# EMIF1 register map
Vendor: Texas Instruments
Peripheral module from a debugger description file (folder omap4460).
Registers are 32-bit, access per field, reset 0x0 unless marked. A register's access mark holds for its fields unless they carry their own. Offsets are as the file gives them; lines under a group give offsets from that group; [hi:lo] are bit positions; {n}, {i} and the like mark numbered series; 'fields as' and 'values as' point back to an identical list; <NAME> marks a mode.

## EMIF1
0x00 EMIF_MOD_ID_REV ro reset not defined — Revision number register
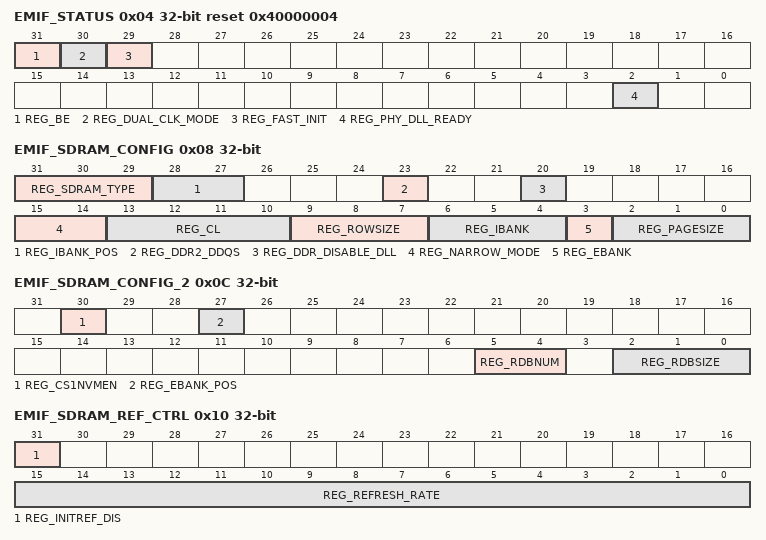
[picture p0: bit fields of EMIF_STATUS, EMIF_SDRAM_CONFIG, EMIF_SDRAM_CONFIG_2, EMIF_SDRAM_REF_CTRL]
0x04 EMIF_STATUS ro reset 0x40000004 — SDRAM Status Register (STATUS)
  [31] REG_BE — Big endian mode select for 8 and 16-bit devices, set to 1 for big endian or 0 for little endian operation.
  [30] REG_DUAL_CLK_MODE — Dual Clock mode. Defines whether the L3_clk and EMIF_FCLK clock are asynchronous. L3_clk and EMIF_FCLK clock are asynchronous, if set to 1.
  [29] REG_FAST_INIT — Fast Init. Defines whether the EMIF fast initialization mode has been enabled. Fast initialization is enabled if set to 1.
  [2] REG_PHY_DLL_READY — DDR PHY Ready. Reflects the value on the phy_ready port (active high) that defines whether the DDR PHY is ready for normal operation. The DDR PHY is ready for normal operation, if set to 1.
0x08 EMIF_SDRAM_CONFIG rw (reset mask 0x70F0000) — SDRAM Config Register. A write to this register will cause the EMIF to start the SDRAM initialization sequence if it was not performed previously because [31] REG_INITREF_DIS was a zero.
  [31:29] REG_SDRAM_TYPE — SDRAM Type selection. Set to 4 for LPDDR2-S4, Set to 5 for LPDDR2-S2 All other value are reserved.
  [28:27] REG_IBANK_POS — Internal bank position. Set to 0 to assign internal bank address bits from L3 address as shown in and . Set to 1, 2, or 3 to assign internal bank address bits from L3 address as shown in , , and .
  [23] REG_DDR2_DDQS — DDR2 differential DQS enable. Set to 0 for single-ended DQS. Set to 1 for differential DQS. This bit is only for DDR2 mode, because the device supports LPDDR2; this bit is don’t care.
  [20] REG_DDR_DISABLE_DLL — Disable DLL select. Set to 1 to disable DLL inside SDRAM.
  [15:14] REG_NARROW_MODE — SDRAM data bus width. Set to 0 for 32-bit and set to 1 for 16-bit. All other values are reserved.
  [13:10] REG_CL — CAS Latency (referred to as read latency (RL) in some SDRAM specs). The value of this field defines the CAS latency to be used when accessing connected SDRAM devices. Value of 3, 4, 5, 6, 7, and 8 (CAS latency of 3, 4, 5, 6, 7, and 8) are supported for LPDDR2-SDRAM. All other values are reserved. Also program the EMIF_DDR_PHY_CTRL_1[3:0] REG_READ_LATENCY
  [9:7] REG_ROWSIZE — Row Size. Defines the number of row address bits of connected SDRAM devices. Set to 0 for 9 row bits, Set to 1 for 10 row bits, Set to 2 for 11 row bits, Set to 3 for 12 row bits, Set to 4 for 13 row bits, Set to 5 for 14 row bits, Set to 6 for 15 row bits, Set to 7 for 16 row bits. This field is only used when EMIF_SDRAM_CONFIG[28:27] REG_IBANK_POS field is set to 1, 2, or 3 or REG_EBANK_POS field in EMIF_SDRAM_CONFIG_2 register is set to 1.
  [6:4] REG_IBANK — Internal Bank setup. Defines number of banks inside connected SDRAM devices. Set to 0 for 1 bank, Set to 1 for 2 banks, Set to 2 for 4 banks, Set to 3 for 8 banks. All other values are reserved.
  [3] REG_EBANK — External chip select setup. Defines whether SDRAM accesses will use 1 or 2 chip select lines. Set to 0 to use pad_cs_o_n[0] only. Set to 1 to use pad_cs_o_n[1:0]. This bit will automatically be set to 0 if EMIF_SDRAM_CONFIG_2[30] REG_CS1NVMEN field is set to 1.
  [2:0] REG_PAGESIZE — Page Size. Defines the internal page size of connected SDRAM devices. Set to 0 for 256-word page (8 column bits), Set to 1 for 512-word page (9 column bits), Set to 2 for 1024-word page (10 column bits), Set to 3 for 2048-word page (11 column bits). All other values are reserved.
0x0C EMIF_SDRAM_CONFIG_2 (reset mask 0xBFFFFFC8)
  [30] REG_CS1NVMEN rw — CS1 LPDDR2-NVM enable. Set to 1 if LPDDR2-NVM is connected to CS1. This bit will automatically be set to 0 if reg_sdram_type field in the SDRAM Config register is not set to LPDDR2.
  [27] REG_EBANK_POS rw — External bank position. Set to 0 to assign external bank address bits from lower OCP address as shown in tables. Set to 1 to assign external bank address bits from higher OCP address bits as shown in tables.
  [5:4] REG_RDBNUM rw — Row Buffer setup. Defines number of row buffers inside connected LPDDR2-NVM devices. Set to 0 for 1 row buffer, set to 1 for 2 row buffers, set to 2 for 4 row buffers, and set to 3 for 8 row buffers. All other values are reserved.
  [2:0] REG_RDBSIZE rw — Row Data Buffer Size. Defines the row data buffer size of connected LPDDR2-NVM devices. Set to 0 for 32 bytes, set to 1 for 64 bytes, set to 2 for 128 bytes, set to 3 for 256 bytes, set to 4 for 512 bytes, set to 5 for 1024 bytes, set to 6 for 2048 bytes, and set to 7 for 4096 bytes.
0x10 EMIF_SDRAM_REF_CTRL — SDRAM Refresh Control Register
  [31] REG_INITREF_DIS rw — Initialization and Refresh disable. When set to 1, EMIF will disable SDRAM initialization and refreshes, but will carry out SDRAM write/read transactions.
  [15:0] REG_REFRESH_RATE rw — Refresh Rate. Value in this field is used to define the rate at which connected SDRAM devices will be refreshed. SDRAM refresh rate = DDR_PHY_CLK / REG_REFRESH_RATE. To avoid lock-up situations, the programmer must not program REG_REFRESH_RATE &lt; (6 × REG_T_RFC). For DDR_PHY_CLK description, see, .
0x14 EMIF_SDRAM_REF_CTRL_SHDW — SDRAM Refresh Control Shadow Register
  [15:0] REG_REFRESH_RATE_SHDW rw — Shadow field for REG_REFRESH_RATE. This field is loaded intoEMIF_SDRAM_REF_CTRL[15:0] REG_REFRESH_RATE field when SIdleAck is asserted. This register is not auto corrected when the value is invalid.
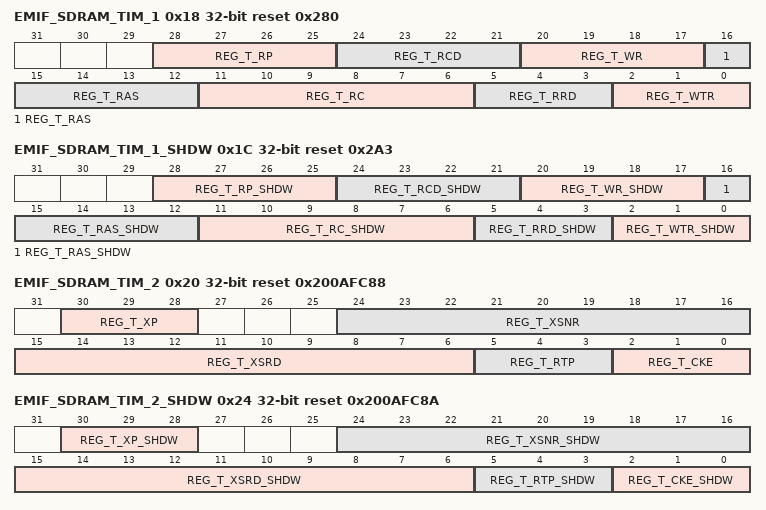
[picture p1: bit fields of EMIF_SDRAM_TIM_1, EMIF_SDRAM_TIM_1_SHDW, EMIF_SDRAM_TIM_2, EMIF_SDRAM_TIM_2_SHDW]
0x18 EMIF_SDRAM_TIM_1 reset 0x280 (reset mask 0xFFFFFFC0) — SDRAM Timing 1 Register. If this register is byte written, care must be taken that all the fields are written before performing any accesses to the SDRAM.
  [28:25] REG_T_RP rw — Minimum number of DDR clock cycles from Precharge to Activate or Refresh, minus one.
  [24:21] REG_T_RCD rw — Minimum number of DDR clock cycles from Activate to Read or Write, minus one.
  [20:17] REG_T_WR rw — Minimum number of DDR clock cycles from last Write transfer to Precharge, minus one.
  [16:12] REG_T_RAS rw — Minimum number of DDR clock cycles from Activate to Precharge, minus one. reg_t_ras value needs to be bigger than or equal to reg_t_rcd value.
  [11:6] REG_T_RC rw — Minimum number of DDR clock cycles from Activate to Activate, minus one.
  [5:3] REG_T_RRD rw — Minimum number of DDR clock cycles from Activate to Activate for a different bank, minus one. For an 8-bank, this field must be equal to ((tFAW/(4*tCK))-1).
  [2:0] REG_T_WTR rw — Minimum number of DDR clock cycles from last Write to Read, minus one.
0x1C EMIF_SDRAM_TIM_1_SHDW reset 0x2A3 — SDRAM Timing 1 Shadow Register
  [28:25] REG_T_RP_SHDW rw — Shadow field for REG_T_RP. This field is loaded intoEMIF_SDRAM_TIM_1[28:25] REG_T_RP field when SIdleAck is asserted.
  [24:21] REG_T_RCD_SHDW rw — Shadow field for REG_T_RCD. This field is loaded intoEMIF_SDRAM_TIM_1[24:21] REG_T_RCD field when SIdleAck is asserted.
  [20:17] REG_T_WR_SHDW rw — Shadow field for REG_T_WR. This field is loaded intoEMIF_SDRAM_TIM_1[20:17] REG_T_WR field when SIdleAck is asserted.
  [16:12] REG_T_RAS_SHDW rw — Shadow field for REG_T_RAS. This field is loaded intoEMIF_SDRAM_TIM_1[16:12] REG_T_RAS field when SIdleAck is asserted.
  [11:6] REG_T_RC_SHDW rw — Shadow field for REG_T_RC. This field is loaded intoEMIF_SDRAM_TIM_1[11:6] REG_T_RC field when SIdleAck is asserted.
  [5:3] REG_T_RRD_SHDW rw — Shadow field for REG_T_RRD. This field is loaded intoEMIF_SDRAM_TIM_1[5:3] REG_T_RRD field when SIdleAck is asserted.
  [2:0] REG_T_WTR_SHDW rw — Shadow field for REG_T_WTR. This field is loaded intoEMIF_SDRAM_TIM_1[2:0] REG_T_WTR field when SIdleAck is asserted.
0x20 EMIF_SDRAM_TIM_2 reset 0x200AFC88 (reset mask 0xFFFFFFF8) — SDRAM Timing 2 Register. If this register is byte written, care must be taken that all the fields are written before performing any accesses to the SDRAM.
  [30:28] REG_T_XP rw — Minimum number of DDR clock cycles from power-down exit to any command other than a read command, minus one.
  [24:16] REG_T_XSNR rw — Minimum number of DDR clock cycles from Self-Refresh exit to any command other than a Read command, minus one. REG_T_XSNR and REG_T_XSRD must be programmed with the same value.
  [15:6] REG_T_XSRD rw — Minimum number of DDR clock cycles from Self-Refresh exit to a Read command, minus one. REG_T_XSNR and REG_T_XSRD must be programmed with the same value.
  [5:3] REG_T_RTP rw — Minimum number of DDR clock cycles for the last read command to a Precharge command, minus one.
  [2:0] REG_T_CKE rw — Minimum number of DDR clock cycles between pad_cke_o changes, minus one.
0x24 EMIF_SDRAM_TIM_2_SHDW reset 0x200AFC8A — SDRAM Timing 2 Shadow Register
  [30:28] REG_T_XP_SHDW rw — Shadow field for REG_T_XP. This field is loaded intoEMIF_SDRAM_TIM_2[30:28] REG_T_XP field when SIdleAck is asserted.
  [24:16] REG_T_XSNR_SHDW rw — Shadow field for REG_T_XSNR. This field is loaded intoEMIF_SDRAM_TIM_2[24:16] REG_T_XSNR field when SIdleAck is asserted.
  [15:6] REG_T_XSRD_SHDW rw — Shadow field for REG_T_XSRD. This field is loaded intoEMIF_SDRAM_TIM_2[15:6] REG_T_XSRD field when SIdleAck is asserted.
  [5:3] REG_T_RTP_SHDW rw — Shadow field for REG_T_RTP. This field is loaded intoEMIF_SDRAM_TIM_2[5:3] REG_T_RTP field when SIdleAck is asserted.
  [2:0] REG_T_CKE_SHDW rw — Shadow field for REG_T_CKE. This field is loaded intoEMIF_SDRAM_TIM_2[2:0] REG_T_CKE field when SIdleAck is asserted.
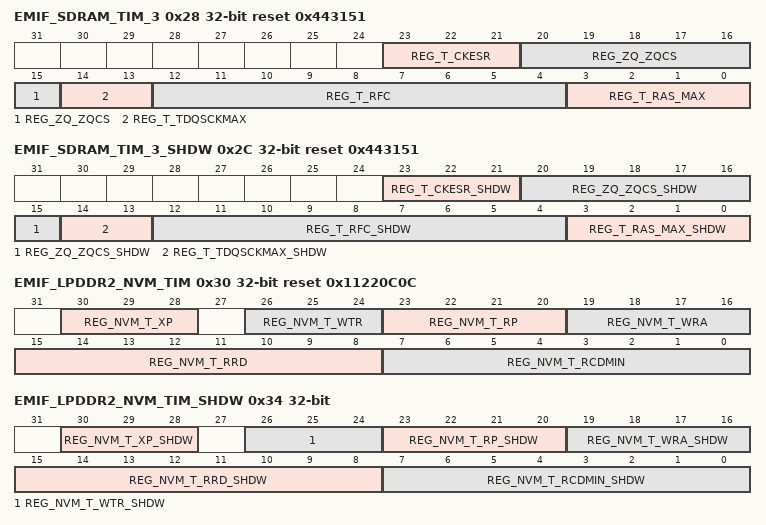
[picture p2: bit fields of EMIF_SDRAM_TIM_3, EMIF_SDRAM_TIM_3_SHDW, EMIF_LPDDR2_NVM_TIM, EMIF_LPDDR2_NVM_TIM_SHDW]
0x28 EMIF_SDRAM_TIM_3 reset 0x443151 — SDRAM Timing 3 Register. If this register is byte written, care must be taken that all the fields are written before performing any accesses to the SDRAM.
  [23:21] REG_T_CKESR rw — Minimum number of DDR clock cycles for which LPDDR2 must remain in Self Refresh, minus one.
  [20:15] REG_ZQ_ZQCS rw — Number of DDR clock cycles for a ZQCS command, minus one.
  [14:13] REG_T_TDQSCKMAX rw — Number of DDR clock that satisfies tDQSCKmax for LPDDR2, minus one.
  [12:4] REG_T_RFC rw — Minimum number of DDR clock cycles from Refresh or Load Mode to Refresh or Activate, minus one.
  [3:0] REG_T_RAS_MAX rw — Maximum number of reg_refresh_rate intervals from Activate to Precharge command. This field must be equal to ((tRASmax / tREFI)-1) rounded down to the next lower integer. Value for REG_T_RAS_MAX can be calculated as follows: If tRASmax = 120 us and tREFI = 15.7 us, then REG_T_RAS_MAX = ((120/15.7)-1) = 6.64. Round down to the next lower integer. Therefore, the programmed value must be 6.
0x2C EMIF_SDRAM_TIM_3_SHDW reset 0x443151 — SDRAM Timing 3 Shadow Register
  [23:21] REG_T_CKESR_SHDW rw — Shadow field for reg_t_ckesr. This field is loaded into reg_t_ckesr field inEMIF_SDRAM_TIM_3 register when SIdleAck is asserted.
  [20:15] REG_ZQ_ZQCS_SHDW rw — Shadow field for reg_zq_zqcs. This field is loaded into reg_zq_zqcs field inEMIF_SDRAM_TIM_3 register when SIdleAck is asserted.
  [14:13] REG_T_TDQSCKMAX_SHDW rw — Shadow field for REG_T_TDQSCKMAX. This field is loaded intoEMIF_SDRAM_TIM_3[14:13] REG_T_TDQSCKMAX field when SIdleAck is asserted.
  [12:4] REG_T_RFC_SHDW rw — Shadow field for REG_T_RFC. This field is loaded intoEMIF_SDRAM_TIM_3[12:4] REG_T_RFC when SIdleAck is asserted.
  [3:0] REG_T_RAS_MAX_SHDW rw — Shadow field for REG_T_RAS_MAX. This field is loaded intoEMIF_SDRAM_TIM_3[3:0] REG_T_RAS_MAX field when SIdleAck is asserted.
0x30 EMIF_LPDDR2_NVM_TIM reset 0x11220C0C — LPDDR2-NVM Timing Register. If this register is byte written, care must be taken that all the fields are written before performing any accesses to the LPDDR2-NVM. NOT USED.
  [30:28] REG_NVM_T_XP rw — Minimum number of DDR clock cycles from power-down exit to any command minus one.
  [26:24] REG_NVM_T_WTR rw — Minimum number of DDR clock cycles from last Write to Read, minus one.
  [23:20] REG_NVM_T_RP rw — Minimum number of DDR clock cycles from Preactive to Activate, minus one.
  [19:16] REG_NVM_T_WRA rw — Minimum number of DDR clock cycles from last Write transfer to Activate, minus one.
  [15:8] REG_NVM_T_RRD rw — Minimum number of DDR clock cycles from Activate to Activate for a different bank, minus one.
  [7:0] REG_NVM_T_RCDMIN rw — Minimum number of DDR clock cycles from Activate to Read or Write, minus one.
0x34 EMIF_LPDDR2_NVM_TIM_SHDW — LPDDR2-NVM Timing Shadow Register
  [30:28] REG_NVM_T_XP_SHDW rw — Shadow field for REG_NVM_T_XP. This field is loaded intoEMIF_LPDDR2_NVM_TIM[30:28] REG_NVM_T_XP field when SIdleAck is asserted.
  [26:24] REG_NVM_T_WTR_SHDW rw — Shadow field for REG_NVM_T_WTR. This field is loaded intoEMIF_LPDDR2_NVM_TIM[26:24] REG_NVM_T_WTR field when SIdleAck is asserted.
  [23:20] REG_NVM_T_RP_SHDW rw — Shadow field for REG_NVM_T_RP. This field is loaded intoEMIF_LPDDR2_NVM_TIM[23:20] REG_NVM_T_RP field when SIdleAck is asserted.
  [19:16] REG_NVM_T_WRA_SHDW rw — Shadow field for REG_NVM_T_WRA. This field is loaded intoEMIF_LPDDR2_NVM_TIM[19:16] REG_NVM_T_WRA field when SIdleAck is asserted.
  [15:8] REG_NVM_T_RRD_SHDW rw — Shadow field for REG_NVM_T_RRD. This field is loaded intoEMIF_LPDDR2_NVM_TIM[15:8] REG_NVM_T_RRD field when SIdleAck is asserted.
  [7:0] REG_NVM_T_RCDMIN_SHDW rw — Shadow field for . This field is loaded intoEMIF_LPDDR2_NVM_TIM[7:0] REG_NVM_T_RCDMIN field when SIdleAck is asserted.
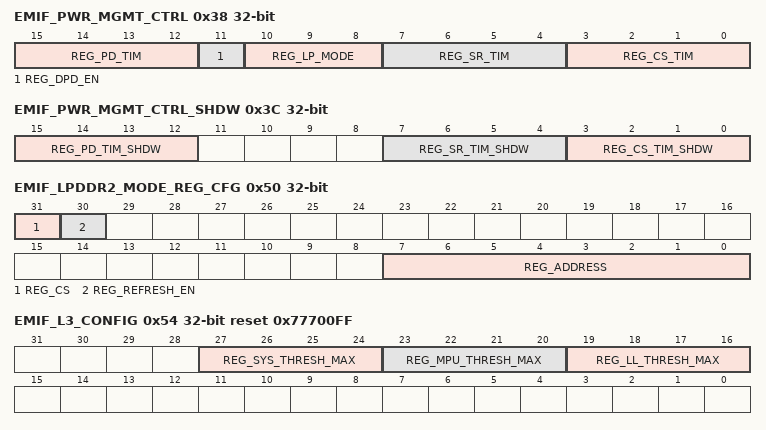
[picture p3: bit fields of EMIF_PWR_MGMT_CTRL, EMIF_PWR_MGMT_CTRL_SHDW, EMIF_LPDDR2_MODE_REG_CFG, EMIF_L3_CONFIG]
0x38 EMIF_PWR_MGMT_CTRL — Power Management Control Register
  [15:12] REG_PD_TIM rw — Power Mangement timer for Power-Down. The EMIF will put the external SDRAM in Power-Down mode after the EMIF is idle for these number of DDR clock cycles and if reg_lp_mode field is set to 4. Set to 0 to immediately enter Power-Down mode. Set to 1 for 16 clocks, set to 2 for 32 clocks, set to 3 for 64 clocks, set to 4 for 128 clocks, set to 5 for 256 clocks, set to 6 for 512 clocks, set to 7 for 1024 clocks, set to 8 for 2048 clocks, set to 9 for 4096 clocks, set to 10 for 8192 clocks, set to 11 for 16384 clocks, set to 12 for 32768 clocks, set to 13 for 65536 clocks, set to 14 for 131072 clocks, and set to 15 for 262144 clocks.
  [11] REG_DPD_EN rw — Deep Power Down enable. Set to 0 for normal operation. Set to 1 to enter deep power-down mode. This mode will override the reg_lp_mode field setting.
  [10:8] REG_LP_MODE rw — Automatic Power Management enableSet to 1: Reserved . Set to 2: Self-refresh mode . Set to 4: Power-down mode . All other values will disable automatic power management. .
  [7:4] REG_SR_TIM rw — Power Mangement timer for Self Refresh. The EMIF will put the external SDRAM in Self Refresh mode after the EMIF is idle for these number of DDR clock cycles and if reg_lp_mode field is set to 2. Set to 0 to immediately enter Self Refresh mode. Set to 1 for 16 clocks, set to 2 for 32 clocks, set to 3 for 64 clocks, set to 4 for 128 clocks, set to 5 for 256 clocks, set to 6 for 512 clocks, set to 7 for 1024 clocks, set to 8 for 2048 clocks, set to 9 for 4096 clocks, set to 10 for 8192 clocks, set to 11 for 16384 clocks, set to 12 for 32768 clocks, set to 13 for 65536 clocks, set to 14 for 131072 clocks, and set to 15 for 262144 clocks.
  [3:0] REG_CS_TIM rw — Power Mangement timer for Clock Stop. The EMIF will put the external SDRAM in Clock Stop mode after the EMIF is idle for these number of DDR clock cycles and if reg_lp_mode field is set to 1. Set to 0 to immediately enter Clock Stop mode. Set to 1 for 16 clocks, set to 2 for 32 clocks, set to 3 for 64 clocks, set to 4 for 128 clocks, set to 5 for 256 clocks, set to 6 for 512 clocks, set to 7 for 1024 clocks, set to 8 for 2048 clocks, set to 9 for 4096 clocks, set to 10 for 8192 clocks, set to 11 for 16384 clocks, set to 12 for 32768 clocks, set to 13 for 65536 clocks, set to 14 for 131072 clocks, and set to 15 for 262144 clocks.
0x3C EMIF_PWR_MGMT_CTRL_SHDW — Power Management Control Shadow Register
  [15:12] REG_PD_TIM_SHDW rw — Shadow field for reg_pd_tim. This field is loaded into reg_pd_tim field in Power Management Control register when SIdleAck is asserted.
  [7:4] REG_SR_TIM_SHDW rw — Shadow field for reg_sr_tim. This field is loaded into reg_sr_tim field in Power Management Control register when SIdleAck is asserted.
  [3:0] REG_CS_TIM_SHDW rw — Shadow field for reg_cs_tim. This field is loaded into reg_cs_tim field in Power Management Control register when SIdleAck is asserted.
0x40 EMIF_LPDDR2_MODE_REG_DATA — LPDDR2 Mode Reg Data Register A write to this register will cause a Mode Register write command to be sent to the LPDDR2 device with write data as specified in the REG_VALUE_0 field. The address and chip select are taken from the LPDDR2_MODE_REG_CFG register. A read to this register will cause a Mode Register read command to be sent to the LPDDR2 device. The address and chip select are taken from the LPDDR2_MODE_REG_CFG register. The read data will appear in REG_VALUE_0 field.
  [7:0] REG_VALUE_0 rw — Mode register value.
0x50 EMIF_LPDDR2_MODE_REG_CFG — LPDDR2 Mode Reg Config Register
  [31] REG_CS rw — Chip select to issue mode register command. Set to 0 for CS0 and set to 1 for CS1.
  [30] REG_REFRESH_EN rw — Refresh Enable after MRW write. If a Mode Data register write occurs with this bit set to 1, the refresh operations will commence.
  [7:0] REG_ADDRESS rw — Mode register address.
0x54 EMIF_L3_CONFIG reset 0x77700FF — Config Register
  [27:24] REG_SYS_THRESH_MAX rw — System L3 Threshold Maximum. The number of commands the system interface can consume in the command FIFO. The value is used to determine when to stop future request, writing a zero will reserve no space for the associated interface. In the event the value is set to zero and a request is seen for that interface, the command FIFO will assume a value of 1. Since the low-latency interface has effectively a higher priority, the only way for the system interface to use all command FIFO entries is to set the REG_LL_THRESH_MAX to zero.
  [23:20] REG_MPU_THRESH_MAX rw — MPU Interface Threshold Maximum. The number of commands the MPU interface can consume in the command FIFO. The value is used to determine when to stop future request, writing a zero will reserve no space for the associated interface. In the event the value is set to zero and a request is seen for that interface, the command FIFO will assume a value of 1.
  [19:16] REG_LL_THRESH_MAX rw — Low-latency L3 Threshold Maximum. The number of commands the low latency interface can consume in the command FIFO. The value is used to determine when to stop future request, writing a zero will reserve no space for the associated interface. In the event the value is set to zero and a request is seen for that interface, the command FIFO will assume a value of 1.
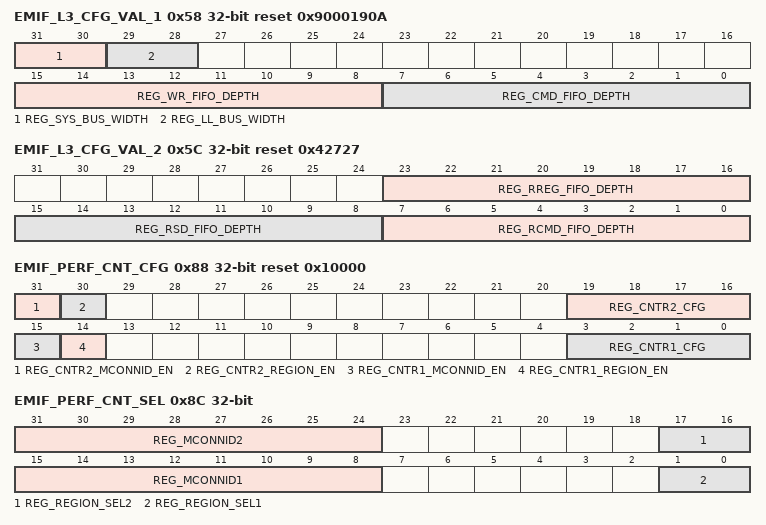
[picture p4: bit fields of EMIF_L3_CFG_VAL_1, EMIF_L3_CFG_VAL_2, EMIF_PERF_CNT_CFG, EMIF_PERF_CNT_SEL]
0x58 EMIF_L3_CFG_VAL_1 ro reset 0x9000190A — Config Value 1 Register
  [31:30] REG_SYS_BUS_WIDTH — System L3 data bus width 0 = 32-bit wide, 1 = 64-bit wide, 2 = 128-bit wide, 3 = Reserved
  [29:28] REG_LL_BUS_WIDTH — Low-latency L3 data bus width 0 = 32-bit wide, 1 = 64-bit wide, 2 = 128-bit wide, 3 = Reserved
  [15:8] REG_WR_FIFO_DEPTH — Write Data FIFO depth
  [7:0] REG_CMD_FIFO_DEPTH — Command FIFO depth
0x5C EMIF_L3_CFG_VAL_2 ro reset 0x42727 — Config Value 2 Register
  [23:16] REG_RREG_FIFO_DEPTH — Register Read Data FIFO depth
  [15:8] REG_RSD_FIFO_DEPTH — SDRAM Read Data FIFO depth
  [7:0] REG_RCMD_FIFO_DEPTH — Read Command FIFO depth
0x80 EMIF_PERF_CNT_1 ro — Performance Counter 1 Register
  [31:0] REG_COUNTER1 — 32-bit counter that can be configured as specified in the Performance Counter Config Register and Performance Counter Master Region Select Register.
0x84 EMIF_PERF_CNT_2 ro — Performance Counter 2 Register
  [31:0] REG_COUNTER2 — 32-bit counter that can be configured as specified in the Performance Counter Config Register and Performance Counter Master Region Select Register.
0x88 EMIF_PERF_CNT_CFG reset 0x10000 — Performance Counter Config Register
  [31] REG_CNTR2_MCONNID_EN rw — MConnID filter enable for Performance Counter 2 register.
  [30] REG_CNTR2_REGION_EN rw — Chip Select filter enable for Performance Counter 2 register.
  [19:16] REG_CNTR2_CFG rw — Filter configuration for Performance Counter 2. Refer to for details.
  [15] REG_CNTR1_MCONNID_EN rw — MConnID filter enable for Performance Counter 1 register.
  [14] REG_CNTR1_REGION_EN rw — Chip Select filter enable for Performance Counter 1 register.
  [3:0] REG_CNTR1_CFG rw — Filter configuration for Performance Counter 1. Refer to for details.
0x8C EMIF_PERF_CNT_SEL — Performance Counter Master Region Select Register
  [31:24] REG_MCONNID2 rw — MConnID for Performance Counter 2 register. The values programmed are those in, , in , , left-shifted by 2 bits.
  [17:16] REG_REGION_SEL2 rw — MAddrSpace for Performance Counter 2 register.
  [15:8] REG_MCONNID1 rw — MConnID for Performance Counter 1 register. The values programmed are those in, , in , , left-shifted by 2 bits.
  [1:0] REG_REGION_SEL1 rw — MAddrSpace for Performance Counter 1 register.
0x90 EMIF_PERF_CNT_TIM ro — Performance Counter Time Register. This is a free running counter.
  [31:0] REG_TOTAL_TIME — 32-bit counter that continuously counts number for EMIF_FCLK clock cycles elapsed after EMIF is brought out of reset.
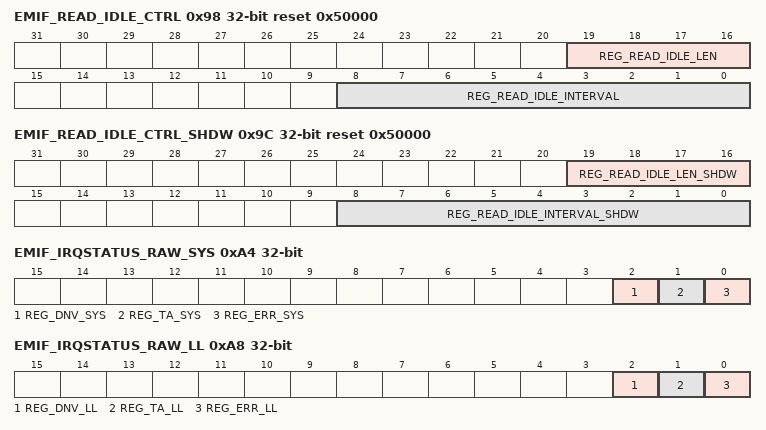
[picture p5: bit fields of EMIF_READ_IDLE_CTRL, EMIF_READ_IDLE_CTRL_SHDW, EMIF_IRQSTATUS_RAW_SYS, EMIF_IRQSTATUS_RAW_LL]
0x98 EMIF_READ_IDLE_CTRL reset 0x50000 — Read Idle Control Register
  [19:16] REG_READ_IDLE_LEN rw — The Read Idle Length field determines the minimum required size that a read idle window must be to be detected or generated. The actual read idle length will be (REG_READ_IDLE_LEN+1)*2 EMIF_FCLK clocks. The value programmed should be (the required read idle length minus one) divided by two.
  [8:0] REG_READ_IDLE_INTERVAL rw — The Read Idle Interval field determines the maximum interval between successive read idle events. The actual interval between read idle events is (REG_READ_IDLE_INTERVAL+1)*64 EMIF_FCLK clocks. The value programmed should be (the required max interval divided by sixty four) minus one. A value of 0 disables the read idle function.
0x9C EMIF_READ_IDLE_CTRL_SHDW reset 0x50000 — Read Idle Control Shadow Register
  [19:16] REG_READ_IDLE_LEN_SHDW rw — Shadow field for REG_READ_IDLE_LEN. This field is loaded intoEMIF_READ_IDLE_CTRL[19:16] REG_READ_IDLE_LEN field when SIdleAck is asserted.
  [8:0] REG_READ_IDLE_INTERVAL_SHDW rw — Shadow field for REG_READ_IDLE_INTERVAL. This field is loaded intoEMIF_READ_IDLE_CTRL[8:0] REG_READ_IDLE_INTERVAL field when SIdleAck is asserted.
0xA4 EMIF_IRQSTATUS_RAW_SYS — System L3 Interrupt Raw Status Register
  [2] REG_DNV_SYS rw — Raw status of system L3 interrupt for LPDDR2 NVM data not valid. Write 1 to set the (raw) status, typically for debug. Writing 0 has no effect.
  [1] REG_TA_SYS rw — Raw status of system L3 interrupt for SDRAM temperature alert. Write 1 to set the (raw) status, mostly for debug. Writing a 0 has no effect.
  [0] REG_ERR_SYS rw — Raw status of system L3 interrupt for command or address error. Write 1 to set the (raw) status, mostly for debug. Writing a 0 has no effect.
0xA8 EMIF_IRQSTATUS_RAW_LL — Low-Latency L3 Interrupt Raw Status Register
  [2] REG_DNV_LL rw — Raw status of low-latency L3 interrupt for LPDDR2 NVM data not valid. Write 1 to set the (raw) status, typically for debug. Writing 0 has no effect.
  [1] REG_TA_LL rw — Raw status of low-latency L3 interrupt or SDRAM temperature alert. Write 1 to set the (raw) status, mostly for debug. Writing a 0 has no effect.
  [0] REG_ERR_LL rw — Raw status of low-latency L3 interrupt for command or address error. Write 1 to set the (raw) status, mostly for debug. Writing a 0 has no effect.
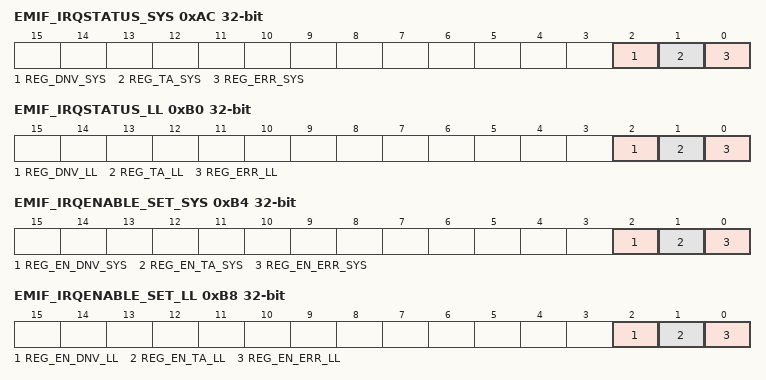
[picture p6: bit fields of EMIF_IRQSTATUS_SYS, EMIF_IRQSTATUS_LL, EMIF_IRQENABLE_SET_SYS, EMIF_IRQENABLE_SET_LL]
0xAC EMIF_IRQSTATUS_SYS — System L3 Interrupt Status Register
  [2] REG_DNV_SYS rw — Enabled status of system L3 interrupt for LPDDR2 NVM data not valid. Write 1 to clear the status after interrupt is serviced (raw status is cleared; that is, even if not enabled). Writing 0 has no effect.
  [1] REG_TA_SYS rw — Enabled status of system L3 interrupt for SDRAM temperature alert. Write 1 to clear the status after interrupt has been serviced (raw status gets cleared, that is, even if not enabled). Writing a 0 has no effect.
  [0] REG_ERR_SYS rw — Enabled status of system L3 interrupt interrupt for command or address error. Write 1 to clear the status after interrupt has been serviced (raw status gets cleared, that is, even if not enabled). Writing a 0 has no effect.
0xB0 EMIF_IRQSTATUS_LL access not given — Low-Latency L3 Interrupt Status Register
  [2] REG_DNV_LL — Enabled status of low-latency L3 interrupt for LPDDR2 NVM data not valid. Write 1 to clear the status after interrupt is serviced (raw status is cleared; that is, even if not enabled). Writing 0 has no effect. (access RW W1toClr)
  [1] REG_TA_LL — Enabled status of low-latency L3 interrupt for SDRAM temperature alert. Write 1 to clear the status after interrupt has been serviced (raw status gets cleared, that is, even if not enabled). Writing a 0 has no effect. (access RW W1toClr)
  [0] REG_ERR_LL — Enabled status of low-latency L3 interrupt for command or address error. Write 1 to clear the status after interrupt has been serviced (raw status gets cleared, that is, even if not enabled). Writing a 0 has no effect. (access RW W1toClr)
0xB4 EMIF_IRQENABLE_SET_SYS access not given — System L3 Interrupt Enable Set Register
  [2] REG_EN_DNV_SYS — Enable set for system L3 interrupt for LPDDR2 NVM data not valid. Writing 1 enables the interrupt and sets this bit and the corresponding Interrupt-enable clear register. Writing 0 has no effect. (access RW W1toSet)
  [1] REG_EN_TA_SYS — Enable set for system L3 interrupt for SDRAM temperature alert. . Writing a 1 will enable the interrupt, and set this bit as well as the corresponding Interrupt Enable Clear Register. Writing a 0 has no effect. (access RW W1toSet)
  [0] REG_EN_ERR_SYS — Enable set for system L3 interrupt for command or address error. Writing a 1 will enable the interrupt, and set this bit as well as the corresponding Interrupt Enable Clear Register. Writing a 0 has no effect. (access RW W1toSet)
0xB8 EMIF_IRQENABLE_SET_LL access not given — Low-Latency L3 Interrupt Enable Set Register
  [2] REG_EN_DNV_LL — Enable set for low-latency L3 interrupt for LPDDR2 NVM data not valid. Writing 1 enables the interrupt and sets this bit and the corresponding Interrupt-enable clear register. Writing a 0 has no effect. (access RW W1toSet)
  [1] REG_EN_TA_LL — Enable set for low-latency L3 interrupt for SDRAM temperature alert. Writing a 1 will enable the interrupt, and set this bit as well as the corresponding Interrupt Enable Clear Register. Writing a 0 has no effect. (access RW W1toSet)
  [0] REG_EN_ERR_LL — Enable set for low-latency L3 interrupt for command or address error. Writing a 1 will enable the interrupt, and set this bit as well as the corresponding Interrupt Enable Clear Register. Writing a 0 has no effect. (access RW W1toSet)
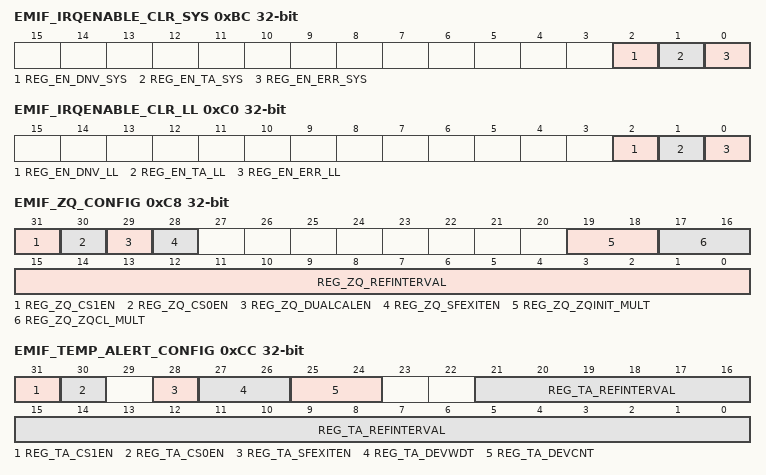
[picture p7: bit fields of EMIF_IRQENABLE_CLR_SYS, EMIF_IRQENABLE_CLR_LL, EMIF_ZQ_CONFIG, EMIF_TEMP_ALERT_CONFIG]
0xBC EMIF_IRQENABLE_CLR_SYS access not given — System L3 Interrupt Enable Clear Register
  [2] REG_EN_DNV_SYS — Enable clear for system OCP interrupt for LPDDR2 NVM data not valid. Writing 1 disables the interrupt and clears this bit and the corresponding interrupt-enable set register. Writing 0 has no effect. (access RW W1toClr)
  [1] REG_EN_TA_SYS — Enable clear for system L3 interrupt for SDRAM temperature alert. Writing a 1 will disable the interrupt, and clear this bit as well as the corresponding Interrupt Enable Set Register. Writing a 0 has no effect. (access RW W1toClr)
  [0] REG_EN_ERR_SYS — Enable clear for system L3 interrupt for command or address error. Writing a 1 will disable the interrupt, and clear this bit as well as the corresponding Interrupt Enable Set Register. Writing a 0 has no effect. (access RW W1toClr)
0xC0 EMIF_IRQENABLE_CLR_LL access not given — Low-Latency L3 Interrupt Enable Clear Register
  [2] REG_EN_DNV_LL — Enable clear for low-latency OCP interrupt for LPDDR2 NVM data not valid. Writing 1 disables the interrupt and clears this bit and the corresponding interrupt enable set register. Writing 0 has no effect. (access RW W1toClr)
  [1] REG_EN_TA_LL — Enable clear for low-latency L3 interrupt for SDRAM temperature alert. Writing a 1 will disable the interrupt, and clear this bit as well as the corresponding Interrupt Enable Set Register. Writing a 0 has no effect. (access RW W1toClr)
  [0] REG_EN_ERR_LL — Enable clear for low-latency L3 interrupt for command or address error. Writing a 1 will disable the interrupt, and clear this bit as well as the corresponding Interrupt Enable Set Register. Writing a 0 has no effect. (access RW W1toClr)
0xC8 EMIF_ZQ_CONFIG — SDRAM Output Impedance Calibration Config Register
  [31] REG_ZQ_CS1EN rw — Writing a 1 enables ZQ calibration for CS1.
  [30] REG_ZQ_CS0EN rw — Writing a 1 enables ZQ calibration for CS0.
  [29] REG_ZQ_DUALCALEN rw — ZQ Dual Calibration enable. Allows both ranks to be ZQ calibrated simultaneously. Setting this bit requires both chip selects to have a separate calibration resistor per device.
  [28] REG_ZQ_SFEXITEN rw — ZQCL on Self-Refresh exit enable. Writing a 1 enables the issuing of ZQCL on Self-Refresh exit.
  [19:18] REG_ZQ_ZQINIT_MULT rw — Indicates the number of ZQCL durations that make up a ZQINIT duration, minus one..
  [17:16] REG_ZQ_ZQCL_MULT rw — Indicates the number of ZQCS intervals that make up a ZQCL duration, minus one. ZQCS interval is defined by reg_zq_zqcs inEMIF_SDRAM_TIM_3.
  [15:0] REG_ZQ_REFINTERVAL rw — Number of refresh periods between ZQCS commands. This field supports between one refresh period to 256 ms between ZQCS calibration commands. Refresh period is defined by reg_refresh_rate inEMIF_SDRAM_REF_CTRL register.
0xCC EMIF_TEMP_ALERT_CONFIG — Temperature Alert Config Register
  [31] REG_TA_CS1EN rw — Writing a 1 enables temperature alert polling for CS1.
  [30] REG_TA_CS0EN rw — Writing a 1 enables temperature alert polling for CS0.
  [28] REG_TA_SFEXITEN rw — Temperature Alert Poll on Self-Refresh, Active Power-Down, and Precharge Power-Down exit enable. Writing a 1 enables the issuing of a temperature alert poll on Self-Refresh exit.
  [27:26] REG_TA_DEVWDT rw — This field indicates how wide a physical device is. It is used in conjunction with the reg_ta_devcnt register to determine which byte lanes contain the temperature alert info. A value of 0 = eight bit wide, 1 = sixteen bit wide, 2 = thirty two bit wide. All others are reserved. If this field is set to 1 and the reg_ta_devcnt field is set to one the byte mask for checking will be 4'b0101.
  [25:24] REG_TA_DEVCNT rw — This field indicates which external byte lanes contain a device for temperature monitoring. A value of 0 = one device, 1 = two devices, 2 = four devices. All other reserved.
  [21:0] REG_TA_REFINTERVAL rw — Number of refresh periods between temperature alert polls. This field supports between one refresh period to 10 seconds between temperature alert polls. Refresh period is defined by reg_refresh_rate in SDRAM Refresh Control register.
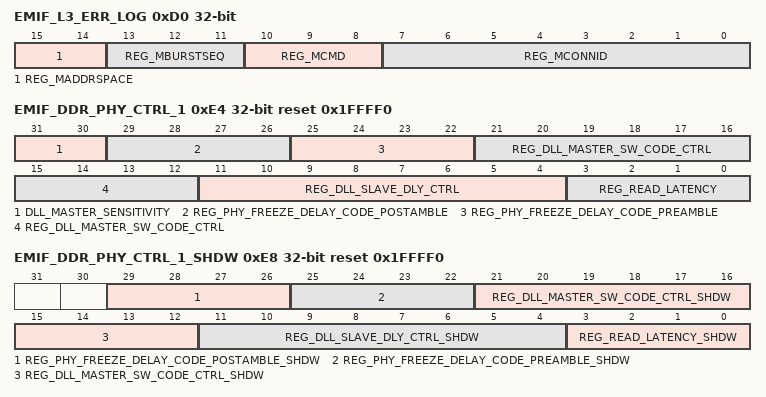
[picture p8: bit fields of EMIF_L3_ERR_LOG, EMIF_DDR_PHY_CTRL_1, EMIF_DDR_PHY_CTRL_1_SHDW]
0xD0 EMIF_L3_ERR_LOG ro — Error Log Register
  [15:14] REG_MADDRSPACE — Address space of the first errored transaction. 0x0: SDRAM 0x1: LPDDR2-NVM 0x2: reserved 0x3: internal registers
  [13:11] REG_MBURSTSEQ — Addressing mode of the first errored transaction. (see, for more information)
  [10:8] REG_MCMD — Command type of the first errored transaction. (see, for more information)
  [7:0] REG_MCONNID — Connection ID of the first errored transaction.
0xE4 EMIF_DDR_PHY_CTRL_1 rw reset 0x1FFFF0 — DDR PHY Control 1 Register. This register is used to control the DDR PHY. The bit field definitions are DDR PHY specific.
  [31:30] DLL_MASTER_SENSITIVITY — This field defines the level of sensitivity of the DLL master: the lower the value, the more sensitive the DLL is to PVT variation. The recommended setting is 0x2.
  [29:26] REG_PHY_FREEZE_DELAY_CODE_POSTAMBLE — Postamble time respected by the DATA PHY freezing the DLL slave code after reads
  [25:22] REG_PHY_FREEZE_DELAY_CODE_PREAMBLE — Preamble time respected by the DATA PHY before freezing the DLL slave code during reads
  [21:12] REG_DLL_MASTER_SW_CODE_CTRL — DLL delay code when in software override mode
  [11:4] REG_DLL_SLAVE_DLY_CTRL — DLL slave delay ratio control
  [3:0] REG_READ_LATENCY — This field defines the read latency for the read data from SDRAM in number of DDR clock cycles. This field is used by the EMIF as well as the PHY. The EMIF will expect the first read data to arrive (reg_read_latency + 3) DDR clock cycles from the read command. The REG_READ_LATENCY must be set to RL +EMIF_SDRAM_TIM_3 [14:13] REG_T_TDQSCKMAX , where REG_T_TDQSCKMAX = ceiling(tDQSCKmax / tCKavg) - 1 The write latency (WL) is tied to the RL. See the LPDDR2 SDRAM standard.
0xE8 EMIF_DDR_PHY_CTRL_1_SHDW rw reset 0x1FFFF0 — DDR PHY Control 1 Shadow Register. Shadow field for.
  [29:26] REG_PHY_FREEZE_DELAY_CODE_POSTAMBLE_SHDW — Shadow field for REG_PHY_FREEZE_DELAY_CODE_POSTAMBLE
  [25:22] REG_PHY_FREEZE_DELAY_CODE_PREAMBLE_SHDW — Shadow field for REG_PHY_FREEZE_DELAY_CODE_PREAMBLE
  [21:12] REG_DLL_MASTER_SW_CODE_CTRL_SHDW — Shadow field for REG_DLL_MASTER_SW_CODE_CTRL
  [11:4] REG_DLL_SLAVE_DLY_CTRL_SHDW — Shadow field for REG_DLL_SLAVE_DLY_CTRL
  [3:0] REG_READ_LATENCY_SHDW — Shadow field for REG_READ_LATENCY. This field is loaded intoEMIF_DDR_PHY_CTRL_1[3:0] REG_READ_LATENCY field when SIdleAck is asserted.
0xEC EMIF_DDR_PHY_CTRL_2 rw — DDR PHY Control 2 Register
  [31:0] REG_DDR_PHY_CTRL_2 — This register is used to control the DDR PHY. The bit field definitions are DDR PHY specific.
